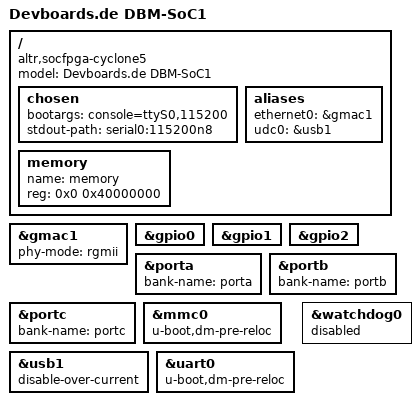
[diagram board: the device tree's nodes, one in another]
// SPDX-License-Identifier: GPL-2.0+
/*
 * Copyright (C) 2018 Marek Vasut <marex@denx.de>
 */

#include "socfpga_cyclone5.dtsi"
#include "socfpga-common-u-boot.dtsi"

/ {
	model = "Devboards.de DBM-SoC1";
	compatible = "altr,socfpga-cyclone5", "altr,socfpga";

	chosen {
		bootargs = "console=ttyS0,115200";
		stdout-path = "serial0:115200n8";
	};

	aliases {
		ethernet0 = &gmac1;
		udc0 = &usb1;
	};

	memory {
		name = "memory";
		device_type = "memory";
		reg = <0x0 0x40000000>; /* 1GB */
	};
};

&gmac1 {
	status = "okay";
	phy-mode = "rgmii";
};

&gpio0 {
	status = "okay";
};

&gpio1 {
	status = "okay";
};

&gpio2 {
	status = "okay";
};

&porta {
	bank-name = "porta";
};

&portb {
	bank-name = "portb";
};

&portc {
	bank-name = "portc";
};

&mmc0 {
	status = "okay";
	u-boot,dm-pre-reloc;
};

&usb1 {
	disable-over-current;
	status = "okay";
};

&uart0 {
	u-boot,dm-pre-reloc;
};

&watchdog0 {
	status = "disabled";
};
